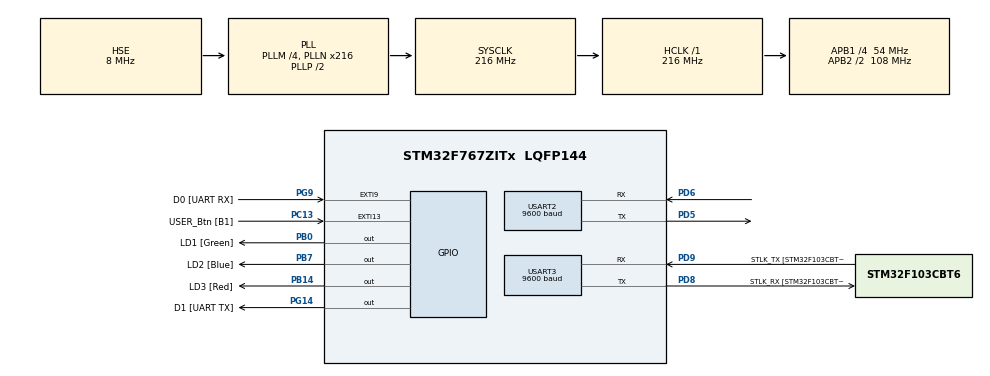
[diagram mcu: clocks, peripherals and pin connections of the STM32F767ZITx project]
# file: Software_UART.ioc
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CORTEX_M7.CPU_DCache=Enabled
CORTEX_M7.CPU_ICache=Enabled
Mcu.Family=STM32F7
Mcu.Name=STM32F767ZITx
Mcu.Package=LQFP144
NVIC.EXTI9_5_IRQn=true\:0\:0\:false\:false\:true\:true\:true
NVIC.PriorityGroup=NVIC_PRIORITYGROUP_4
NVIC.TIM1_UP_TIM10_IRQn=true\:0\:0\:false\:false\:true\:true\:true
PA13.GPIO_Label=TMS
PA13.Mode=Trace_Asynchronous_SW
PA13.Signal=SYS_JTMS-SWDIO
PA14.GPIO_Label=TCK
PA14.Mode=Trace_Asynchronous_SW
PA14.Signal=SYS_JTCK-SWCLK
PB0.GPIO_Label=LD1 [Green]
PB0.Signal=GPIO_Output
PB14.GPIO_Label=LD3 [Red]
PB14.Signal=GPIO_Output
PB3.GPIO_Label=SWO
PB3.Mode=Trace_Asynchronous_SW
PB3.Signal=SYS_JTDO-SWO
PB7.GPIO_Label=LD2 [Blue]
PB7.Signal=GPIO_Output
PC13.GPIO_Label=USER_Btn [B1]
PC13.Signal=GPXTI13
PC14/OSC32_IN.Mode=LSE-External-Oscillator
PC14/OSC32_IN.Signal=RCC_OSC32_IN
PC15/OSC32_OUT.Mode=LSE-External-Oscillator
PC15/OSC32_OUT.Signal=RCC_OSC32_OUT
PD5.Mode=Asynchronous
PD5.Signal=USART2_TX
PD6.Mode=Asynchronous
PD6.Signal=USART2_RX
PD8.GPIO_Label=STLK_RX [STM32F103CBT6_PA3]
PD8.Mode=Asynchronous
PD8.Signal=USART3_TX
PD9.GPIO_Label=STLK_TX [STM32F103CBT6_PA2]
PD9.Mode=Asynchronous
PD9.Signal=USART3_RX
PG14.GPIO_Label=D1 [UART TX]
PG14.GPIO_Speed=GPIO_SPEED_FREQ_VERY_HIGH
PG14.PinState=GPIO_PIN_SET
PG14.Signal=GPIO_Output
PG9.GPIO_Label=D0 [UART RX]
PG9.GPIO_ModeDefaultEXTI=GPIO_MODE_IT_FALLING
PG9.Signal=GPXTI9
PH0/OSC_IN.GPIO_Label=MCO [STM32F103CBT6_PA8]
PH0/OSC_IN.Mode=HSE-External-Clock-Source
PH0/OSC_IN.Signal=RCC_OSC_IN
PH1/OSC_OUT.Mode=HSE-External-Clock-Source
PH1/OSC_OUT.Signal=RCC_OSC_OUT
ProjectManager.HeapSize=0x800
ProjectManager.StackSize=0x1000
ProjectManager.TargetToolchain=STM32CubeIDE
RCC.48MHZClocksFreq_Value=24000000
RCC.AHBFreq_Value=216000000
RCC.APB1CLKDivider=RCC_HCLK_DIV4
RCC.APB1Freq_Value=54000000
RCC.APB1TimFreq_Value=108000000
RCC.APB2CLKDivider=RCC_HCLK_DIV2
RCC.APB2Freq_Value=108000000
RCC.APB2TimFreq_Value=216000000
RCC.CortexFreq_Value=216000000
RCC.HCLKFreq_Value=216000000
RCC.HSE_VALUE=8000000
RCC.HSI_VALUE=16000000
RCC.PLLM=4
RCC.PLLMUL=RCC_PLL_MUL9
RCC.PLLN=216
RCC.PLLQ=4
RCC.PLLSourceVirtual=RCC_PLLSOURCE_HSE
RCC.PRESCALERUSB=RCC_USBCLKSOURCE_PLL_DIV1_5
RCC.SYSCLKFreq_VALUE=216000000
RCC.SYSCLKSource=RCC_SYSCLKSOURCE_PLLCLK
RCC.SYSCLKSourceVirtual=RCC_SYSCLKSOURCE_PLLCLK
RCC.USBFreq_Value=108000000
RCC.VCOOutputFreq_Value=432000000
TIM10.Period=216000000/9600
TIM10.Prescaler=0
USART2.BaudRate=9600
USART2.VirtualMode-Asynchronous=VM_ASYNC
USART3.BaudRate=9600
USART3.VirtualMode-Asynchronous=VM_ASYNC
VP_TIM10_VS_ClockSourceINT.Mode=Enable_Timer
board=NUCLEO-F767ZI

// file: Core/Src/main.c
/* USER CODE BEGIN Header */
/**
  ******************************************************************************
  * @file           : main.c
  * @brief          : Main program body
  ******************************************************************************
  * @attention
  *
  * <h2><center>&copy; Copyright (c) 2020 STMicroelectronics.
  * All rights reserved.</center></h2>
  *
  * This software component is licensed by ST under BSD 3-Clause license,
  * the "License"; You may not use this file except in compliance with the
  * License. You may obtain a copy of the License at:
  *                        opensource.org/licenses/BSD-3-Clause
  *
  ******************************************************************************
  */
/* USER CODE END Header */

#include "main.h"
#include "tim.h"
#include "usart.h"
#include "gpio.h"

/* USER CODE BEGIN Includes */
#include "stdbool.h"
#include "string.h"
#include "stdio.h"
#include "dwt_stm32f7_delay.h"
#include "softuart.h"
/* USER CODE END Includes */

/* USER CODE BEGIN PV */
char g_char[64];
/* USER CODE END PV */

void SystemClock_Config(void);

int main(void)
{

  /* Enable I-Cache---------------------------------------------------------*/
  SCB_EnableICache();

  /* Enable D-Cache---------------------------------------------------------*/
  SCB_EnableDCache();

  /* MCU Configuration--------------------------------------------------------*/

  /* Reset of all peripherals, Initializes the Flash interface and the Systick. */
  HAL_Init();

  /* Configure the system clock */
  SystemClock_Config();

  /* Initialize all configured peripherals */
  MX_GPIO_Init();
  MX_USART3_UART_Init();
  MX_TIM10_Init();
  MX_USART2_UART_Init();
  /* USER CODE BEGIN 2 */
  DWT_Delay_Init();
  /* USER CODE END 2 */

  /* Infinite loop */
  /* USER CODE BEGIN WHILE */
  while (1)
  {
		UARTReceiveString(g_char, sizeof g_char, 9600);
		printf("%s", g_char);
		UARTSend("ABCD", 921600);
    /* USER CODE END WHILE */

  }
}

void SystemClock_Config(void)
{
  RCC_OscInitTypeDef RCC_OscInitStruct = {0};
  RCC_ClkInitTypeDef RCC_ClkInitStruct = {0};
  RCC_PeriphCLKInitTypeDef PeriphClkInitStruct = {0};

  /** Configure LSE Drive Capability
  */
  HAL_PWR_EnableBkUpAccess();
  /** Configure the main internal regulator output voltage
  */
  __HAL_RCC_PWR_CLK_ENABLE();
  __HAL_PWR_VOLTAGESCALING_CONFIG(PWR_REGULATOR_VOLTAGE_SCALE1);
  /** Initializes the CPU, AHB and APB busses clocks
  */
  RCC_OscInitStruct.OscillatorType = RCC_OSCILLATORTYPE_HSE;
  RCC_OscInitStruct.HSEState = RCC_HSE_BYPASS;
  RCC_OscInitStruct.PLL.PLLState = RCC_PLL_ON;
  RCC_OscInitStruct.PLL.PLLSource = RCC_PLLSOURCE_HSE;
  RCC_OscInitStruct.PLL.PLLM = 4;
  RCC_OscInitStruct.PLL.PLLN = 216;
  RCC_OscInitStruct.PLL.PLLP = RCC_PLLP_DIV2;
  RCC_OscInitStruct.PLL.PLLQ = 4;
  if (HAL_RCC_OscConfig(&RCC_OscInitStruct) != HAL_OK)
  {
    Error_Handler();
  }
  /** Activate the Over-Drive mode
  */
  if (HAL_PWREx_EnableOverDrive() != HAL_OK)
  {
    Error_Handler();
  }
  /** Initializes the CPU, AHB and APB busses clocks
  */
  RCC_ClkInitStruct.ClockType = RCC_CLOCKTYPE_HCLK|RCC_CLOCKTYPE_SYSCLK
                              |RCC_CLOCKTYPE_PCLK1|RCC_CLOCKTYPE_PCLK2;
  RCC_ClkInitStruct.SYSCLKSource = RCC_SYSCLKSOURCE_PLLCLK;
  RCC_ClkInitStruct.AHBCLKDivider = RCC_SYSCLK_DIV1;
  RCC_ClkInitStruct.APB1CLKDivider = RCC_HCLK_DIV4;
  RCC_ClkInitStruct.APB2CLKDivider = RCC_HCLK_DIV2;

  if (HAL_RCC_ClockConfig(&RCC_ClkInitStruct, FLASH_LATENCY_7) != HAL_OK)
  {
    Error_Handler();
  }
  PeriphClkInitStruct.PeriphClockSelection = RCC_PERIPHCLK_USART2|RCC_PERIPHCLK_USART3;
  PeriphClkInitStruct.Usart2ClockSelection = RCC_USART2CLKSOURCE_PCLK1;
  PeriphClkInitStruct.Usart3ClockSelection = RCC_USART3CLKSOURCE_PCLK1;
  if (HAL_RCCEx_PeriphCLKConfig(&PeriphClkInitStruct) != HAL_OK)
  {
    Error_Handler();
  }
}

void Error_Handler(void)
{
}

/************************ (C) COPYRIGHT STMicroelectronics *****END OF FILE****/
